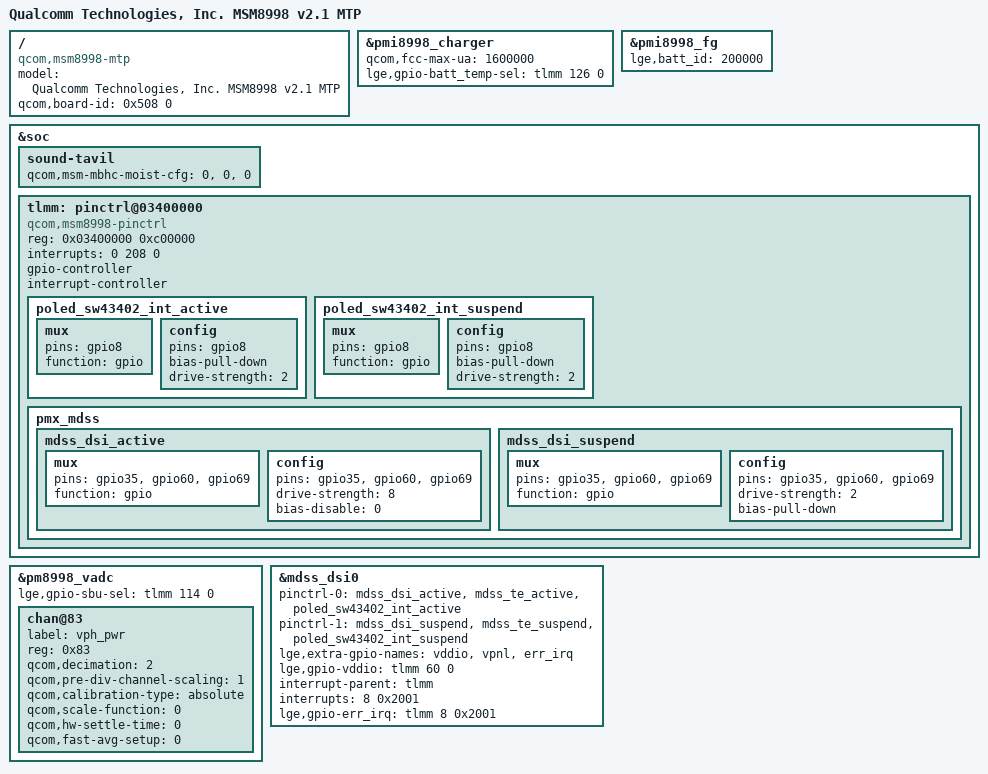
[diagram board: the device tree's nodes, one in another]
/* Copyright (c) 2016, The Linux Foundation. All rights reserved.
 *
 * This program is free software; you can redistribute it and/or modify
 * it under the terms of the GNU General Public License version 2 and
 * only version 2 as published by the Free Software Foundation.
 *
 * This program is distributed in the hope that it will be useful,
 * but WITHOUT ANY WARRANTY; without even the implied warranty of
 * MERCHANTABILITY or FITNESS FOR A PARTICULAR PURPOSE.  See the
 * GNU General Public License for more details.
 */


/dts-v1/;

#include "../../../qcom/msm8998-v2.1.dtsi"
#include "msm8998-joan_kr.dtsi"

/ {
	model = "Qualcomm Technologies, Inc. MSM8998 v2.1 MTP";
	compatible = "qcom,msm8998-mtp", "qcom,msm8998", "qcom,mtp";
	qcom,board-id = <0x508 0>;
};

&pmi8998_charger {
	qcom,fcc-max-ua = <1600000>;
	lge,gpio-batt_temp-sel = <&tlmm 126 0>;
};

&pmi8998_fg {
	lge,batt_id = <200000>;
};

&soc {
	sound-tavil {
		qcom,msm-mbhc-moist-cfg = <0>, <0>, <0>;
	};
};

&pm8998_vadc {
	lge,gpio-sbu-sel = <&tlmm 114 0>;
	chan@83 {
		label = "vph_pwr";
		reg = <0x83>;
		qcom,decimation = <2>;
		qcom,pre-div-channel-scaling = <1>;
		qcom,calibration-type = "absolute";
		qcom,scale-function = <0>;
		qcom,hw-settle-time = <0>;
		qcom,fast-avg-setup = <0>;
    };
};

&mdss_dsi0 {
	pinctrl-names = "mdss_default", "mdss_sleep";
	pinctrl-0 = <&mdss_dsi_active &mdss_te_active &poled_sw43402_int_active>;
	pinctrl-1 = <&mdss_dsi_suspend &mdss_te_suspend &poled_sw43402_int_suspend>;

	lge,extra-gpio-names = "vddio", "vpnl", "err_irq";
	lge,gpio-vddio = <&tlmm 60 0>;
	interrupt-parent = <&tlmm>;
	interrupts = <8 0x2001>; /*IRQF_ONESHOT | IRQF_TRIGGER_RISING*/
	lge,gpio-err_irq =  <&tlmm 8 0x2001>; /* IRQF_ONESHOT | IRQF_TRIGGER_RISING */
};

&soc {
	tlmm: pinctrl@03400000 {
		compatible = "qcom,msm8998-pinctrl";
		reg = <0x03400000 0xc00000>;
		interrupts = <0 208 0>;
		gpio-controller;
		#gpio-cells = <2>;
		interrupt-controller;
		#interrupt-cells = <2>;

		poled_sw43402_int_active:poled_sw43402_int_active {
			mux {
				pins = "gpio8";
				function = "gpio";
			};

			config {
				pins = "gpio8";
				bias-pull-down;
				drive-strength = <2>; /* 2 MA */
			};
		};

		poled_sw43402_int_suspend:poled_sw43402_int_suspend {
			mux {
				pins = "gpio8";
				function = "gpio";
			};

			config {
				pins = "gpio8";
				bias-pull-down;
				drive-strength = <2>; /* 2 MA */
			};
		};

		pmx_mdss: pmx_mdss {
			mdss_dsi_active: mdss_dsi_active {
				mux {
					pins = "gpio35", "gpio60", "gpio69";
					function = "gpio";
				};

				config {
					pins = "gpio35", "gpio60", "gpio69";
					drive-strength = <8>; /* 8 mA */
					bias-disable = <0>; /* no pull */
				};
			};
			mdss_dsi_suspend: mdss_dsi_suspend {
				mux {
					pins = "gpio35", "gpio60", "gpio69";
					function = "gpio";
				};

				config {
					pins = "gpio35", "gpio60", "gpio69";
					drive-strength = <2>; /* 2 mA */
					bias-pull-down; /* pull down */
				};
			};
		};
	};
};
